# STM32F405RGT6 register map
Vendor: STMicroelectronics; File version: 0.1.0
CPU: Cortex-M4 r0p1, little endian, MPU, FPU, DSP, VTOR, 4 interrupt priority bits
Registers are 32-bit, read-write, reset 0x0 unless marked. A register's access mark holds for its fields unless they carry their own. Offsets are from the block's base; [hi:lo] are bit positions; {n}, {i} and the like mark numbered series; 'fields as' and 'values as' point back to an identical list.

## TIM10 — General-purpose-timers
Base 0x40014400
Same registers: TIM13 0x40001C00, TIM14 0x40002000
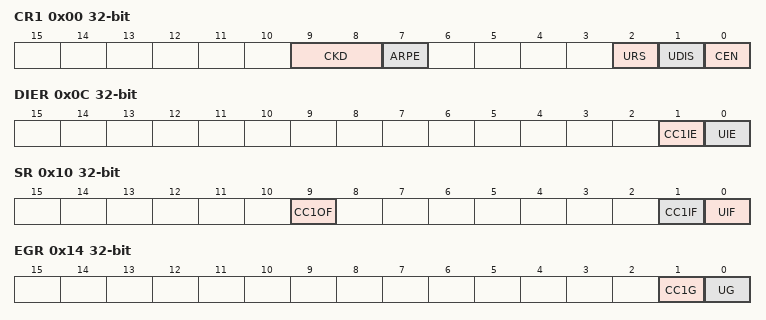
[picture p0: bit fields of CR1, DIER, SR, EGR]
0x00 CR1 — control register 1
  [9:8] CKD — Clock division
  [7] ARPE — Auto-reload preload enable
  [2] URS — Update request source
  [1] UDIS — Update disable
  [0] CEN — Counter enable
0x0C DIER — DMA/Interrupt enable register
  [1] CC1IE — Capture/Compare 1 interrupt enable
  [0] UIE — Update interrupt enable
0x10 SR — status register
  [9] CC1OF — Capture/Compare 1 overcapture flag
  [1] CC1IF — Capture/compare 1 interrupt flag
  [0] UIF — Update interrupt flag
0x14 EGR wo — event generation register
  [1] CC1G — Capture/compare 1 generation
  [0] UG — Update generation
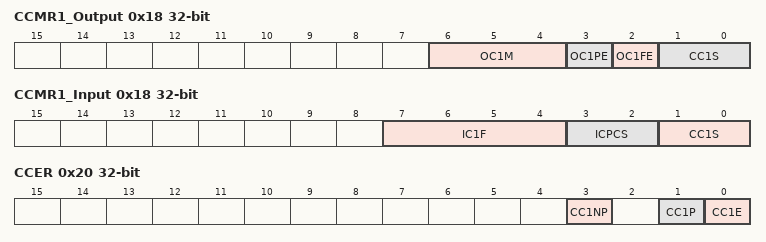
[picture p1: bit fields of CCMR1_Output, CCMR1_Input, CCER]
0x18 CCMR1_Output — capture/compare mode register 1 (output mode)
  [6:4] OC1M — Output Compare 1 mode
  [3] OC1PE — Output Compare 1 preload enable
  [2] OC1FE — Output Compare 1 fast enable
  [1:0] CC1S — Capture/Compare 1 selection
0x18 CCMR1_Input (alternate view of CCMR1_Output) — capture/compare mode register 1 (input mode)
  [7:4] IC1F — Input capture 1 filter
  [3:2] ICPCS — Input capture 1 prescaler
  [1:0] CC1S — Capture/Compare 1 selection
0x20 CCER — capture/compare enable register
  [3] CC1NP — Capture/Compare 1 output Polarity
  [1] CC1P — Capture/Compare 1 output Polarity
  [0] CC1E — Capture/Compare 1 output enable
0x24 CNT — counter
  [15:0] CNT — counter value
0x28 PSC — prescaler
  [15:0] PSC — Prescaler value
0x2C ARR — auto-reload register
  [15:0] ARR — Auto-reload value
0x34 CCR1 — capture/compare register 1
  [15:0] CCR1 — Capture/Compare 1 value

## TIM11 — General-purpose-timers
Base 0x40014800
Registers as TIM10; these are added or differ:
0x50 OR — option register
  [1:0] RMP — Input 1 remapping capability

## TIM6 — Basic timers
Base 0x40001000
Same registers: TIM7 0x40001400
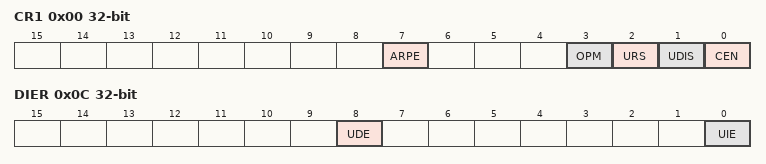
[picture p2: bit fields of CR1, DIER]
0x00 CR1 — control register 1
  [7] ARPE — Auto-reload preload enable
  [3] OPM — One-pulse mode
  [2] URS — Update request source
  [1] UDIS — Update disable
  [0] CEN — Counter enable
0x04 CR2 — control register 2
  [6:4] MMS — Master mode selection
0x0C DIER — DMA/Interrupt enable register
  [8] UDE — Update DMA request enable
  [0] UIE — Update interrupt enable
0x10 SR — status register
  [0] UIF — Update interrupt flag
0x14 EGR wo — event generation register
  [0] UG — Update generation
0x24 CNT — counter
  [15:0] CNT — Low counter value
0x28 PSC — prescaler
  [15:0] PSC — Prescaler value
0x2C ARR — auto-reload register
  [15:0] ARR — Low Auto-reload value

## CRC — Cryptographic processor
Base 0x40023000
0x00 DR reset 0xFFFFFFFF — Data register
  [31:0] DR — Data Register
0x04 IDR — Independent Data register
  [7:0] IDR
0x08 CR wo — Control register
  [0] CR — Control regidter

## OTG_FS_HOST — USB on the go full speed
Base 0x50000400
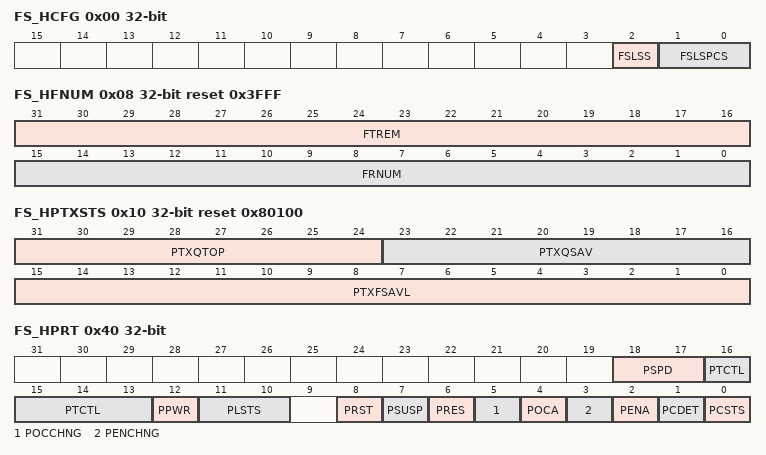
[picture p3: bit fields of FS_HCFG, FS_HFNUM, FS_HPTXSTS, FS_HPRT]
0x00 FS_HCFG access per field — OTG_FS host configuration register (OTG_FS_HCFG)
  [2] FSLSS ro — FS- and LS-only support
  [1:0] FSLSPCS rw — FS/LS PHY clock select
0x04 HFIR reset 0xEA60 — OTG_FS Host frame interval register
  [15:0] FRIVL — Frame interval
0x08 FS_HFNUM ro reset 0x3FFF — OTG_FS host frame number/frame time remaining register (OTG_FS_HFNUM)
  [31:16] FTREM — Frame time remaining
  [15:0] FRNUM — Frame number
0x10 FS_HPTXSTS access per field reset 0x80100 — OTG_FS_Host periodic transmit FIFO/queue status register (OTG_FS_HPTXSTS)
  [31:24] PTXQTOP ro — Top of the periodic transmit request queue
  [23:16] PTXQSAV ro — Periodic transmit request queue space available
  [15:0] PTXFSAVL rw — Periodic transmit data FIFO space available
0x14 HAINT ro — OTG_FS Host all channels interrupt register
  [15:0] HAINT — Channel interrupts
0x18 HAINTMSK — OTG_FS host all channels interrupt mask register
  [15:0] HAINTM — Channel interrupt mask
0x40 FS_HPRT access per field — OTG_FS host port control and status register (OTG_FS_HPRT)
  [18:17] PSPD ro — Port speed
  [16:13] PTCTL rw — Port test control
  [12] PPWR rw — Port power
  [11:10] PLSTS ro — Port line status
  [8] PRST rw — Port reset
  [7] PSUSP rw — Port suspend
  [6] PRES rw — Port resume
  [5] POCCHNG rw — Port overcurrent change
  [4] POCA ro — Port overcurrent active
  [3] PENCHNG rw — Port enable/disable change
  [2] PENA rw — Port enable
  [1] PCDET rw — Port connect detected
  [0] PCSTS ro — Port connect status
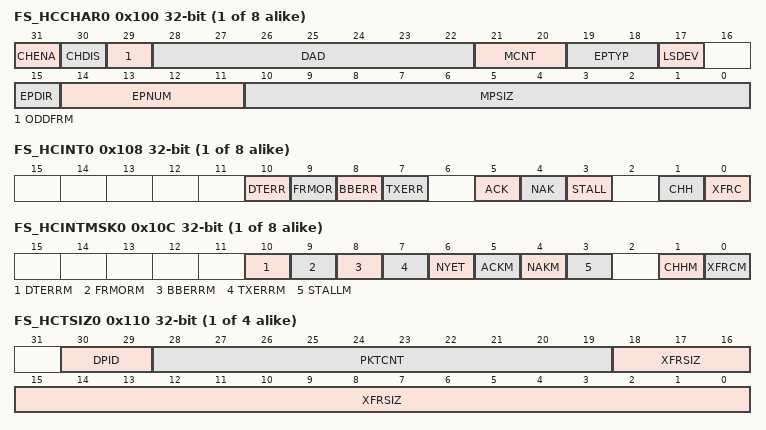
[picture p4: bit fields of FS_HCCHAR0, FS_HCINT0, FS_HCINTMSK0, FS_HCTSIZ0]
{0x100+0x20*i} FS_HCCHAR{i} (i=0..7) — OTG_FS host channel-{i} characteristics register (OTG_FS_HCCHAR{i})
  [31] CHENA — Channel enable
  [30] CHDIS — Channel disable
  [29] ODDFRM — Odd frame
  [28:22] DAD — Device address
  [21:20] MCNT — Multicount
  [19:18] EPTYP — Endpoint type
  [17] LSDEV — Low-speed device
  [15] EPDIR — Endpoint direction
  [14:11] EPNUM — Endpoint number
  [10:0] MPSIZ — Maximum packet size
{0x108+0x20*i} FS_HCINT{i} (i=0..7) — OTG_FS host channel-{i} interrupt register (OTG_FS_HCINT{i})
  [10] DTERR — Data toggle error
  [9] FRMOR — Frame overrun
  [8] BBERR — Babble error
  [7] TXERR — Transaction error
  [5] ACK — ACK response received/transmitted interrupt
  [4] NAK — NAK response received interrupt
  [3] STALL — STALL response received interrupt
  [1] CHH — Channel halted
  [0] XFRC — Transfer completed
{0x10C+0x20*i} FS_HCINTMSK{i} (i=0..7) — OTG_FS host channel-{i} mask register (OTG_FS_HCINTMSK{i})
  [10] DTERRM — Data toggle error mask
  [9] FRMORM — Frame overrun mask
  [8] BBERRM — Babble error mask
  [7] TXERRM — Transaction error mask
  [6] NYET — response received interrupt mask
  [5] ACKM — ACK response received/transmitted interrupt mask
  [4] NAKM — NAK response received interrupt mask
  [3] STALLM — STALL response received interrupt mask
  [1] CHHM — Channel halted mask
  [0] XFRCM — Transfer completed mask
{0x110+0x20*i} FS_HCTSIZ{i} (i=0..3) — OTG_FS host channel-{i} transfer size register
  [30:29] DPID — Data PID
  [28:19] PKTCNT — Packet count
  [18:0] XFRSIZ — Transfer size
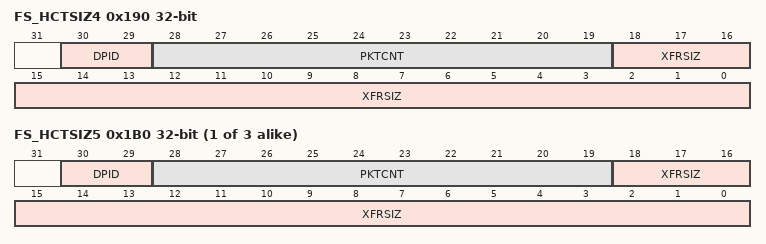
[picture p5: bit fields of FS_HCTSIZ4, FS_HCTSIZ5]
0x190 FS_HCTSIZ4 — OTG_FS host channel-x transfer size register
  fields as FS_HCTSIZ0
{0x110+0x20*i} FS_HCTSIZ{i} (i=5..7) — OTG_FS host channel-{i} transfer size register
  fields as FS_HCTSIZ0

## OTG_FS_PWRCLK — USB on the go full speed
Base 0x50000E00
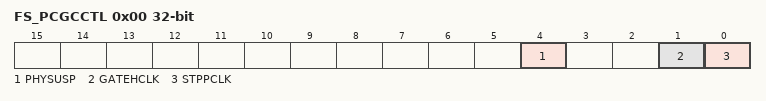
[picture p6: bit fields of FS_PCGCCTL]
0x00 FS_PCGCCTL — OTG_FS power and clock gating control register
  [4] PHYSUSP — PHY Suspended
  [1] GATEHCLK
  [0] STPPCLK — Stop PHY clock

## FLASH
Base 0x40023C00
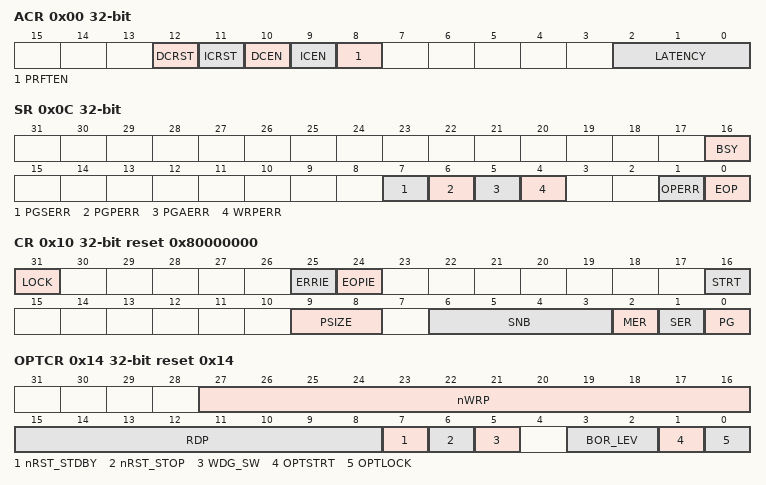
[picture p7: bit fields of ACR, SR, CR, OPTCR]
0x00 ACR access per field — Flash access control register
  [12] DCRST rw — Data cache reset
  [11] ICRST wo — Instruction cache reset
  [10] DCEN rw — Data cache enable
  [9] ICEN rw — Instruction cache enable
  [8] PRFTEN rw — Prefetch enable
  [2:0] LATENCY rw
0x04 KEYR wo — Flash key register
  [31:0] KEY — FPEC key
0x08 OPTKEYR wo — Flash option key register
  [31:0] OPTKEY — Option byte key
0x0C SR access per field — Status register
  [16] BSY ro — Busy
  [7] PGSERR rw — Programming sequence error
  [6] PGPERR rw — Programming parallelism error
  [5] PGAERR rw — Programming alignment error
  [4] WRPERR rw — Write protection error
  [1] OPERR rw — Operation error
  [0] EOP rw — End of operation
0x10 CR reset 0x80000000 — Control register
  [31] LOCK
  [25] ERRIE — Error interrupt enable
  [24] EOPIE — End of operation interrupt enable
  [16] STRT — Start
  [9:8] PSIZE — Program size
  [6:3] SNB — Sector number
  [2] MER — Mass Erase
  [1] SER — Sector Erase
  [0] PG — Programming
0x14 OPTCR reset 0x14 — Flash option control register
  [27:16] nWRP — Not write protect
  [15:8] RDP — Read protect
  [7] nRST_STDBY — nRST_STDBY User option bytes
  [6] nRST_STOP — nRST_STOP User option bytes
  [5] WDG_SW — WDG_SW User option bytes
  [3:2] BOR_LEV — BOR reset Level
  [1] OPTSTRT — Option start
  [0] OPTLOCK — Option lock

## EXTI — External interrupt/event controller
Base 0x40013C00
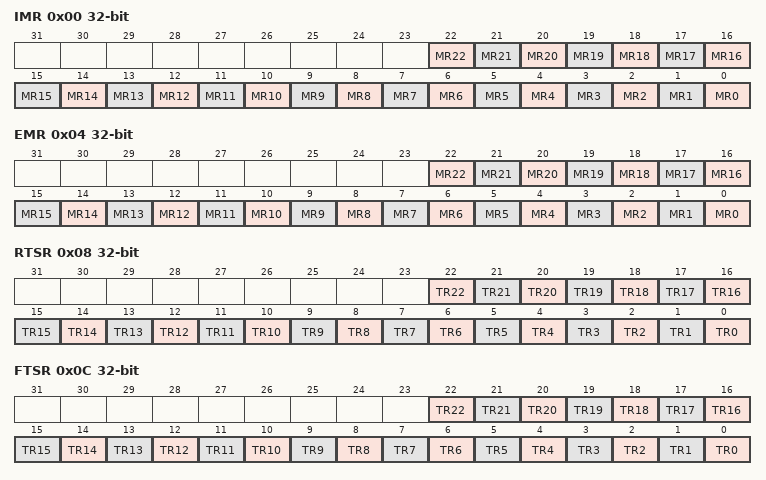
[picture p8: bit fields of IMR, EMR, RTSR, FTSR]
0x00 IMR — Interrupt mask register (EXTI_IMR)
  [n] MR{n} (n=0..22) — Interrupt Mask on line {n}
0x04 EMR — Event mask register (EXTI_EMR)
  [n] MR{n} (n=0..22) — Event Mask on line {n}
0x08 RTSR — Rising Trigger selection register (EXTI_RTSR)
  [n] TR{n} (n=0..22) — Rising trigger event configuration of line {n}
0x0C FTSR — Falling Trigger selection register (EXTI_FTSR)
  [n] TR{n} (n=0..22) — Falling trigger event configuration of line {n}
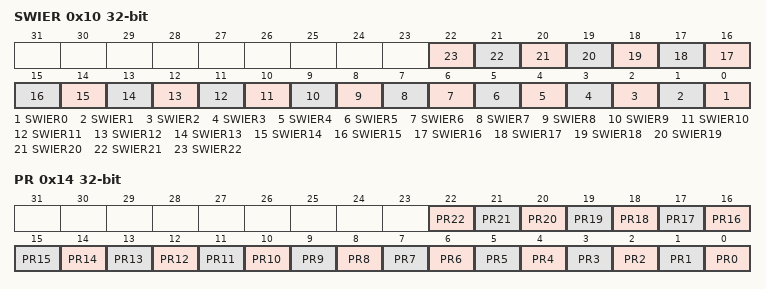
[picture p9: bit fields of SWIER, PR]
0x10 SWIER — Software interrupt event register (EXTI_SWIER)
  [n] SWIER{n} (n=0..22) — Software Interrupt on line {n}
0x14 PR — Pending register (EXTI_PR)
  [n] PR{n} (n=0..22) — Pending bit {n}

## OTG_HS_PWRCLK — USB on the go high speed
Base 0x40040E00
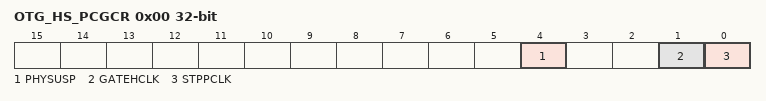
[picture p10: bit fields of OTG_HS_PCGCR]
0x00 OTG_HS_PCGCR — Power and clock gating control register
  [4] PHYSUSP — PHY suspended
  [1] GATEHCLK
  [0] STPPCLK — Stop PHY clock
